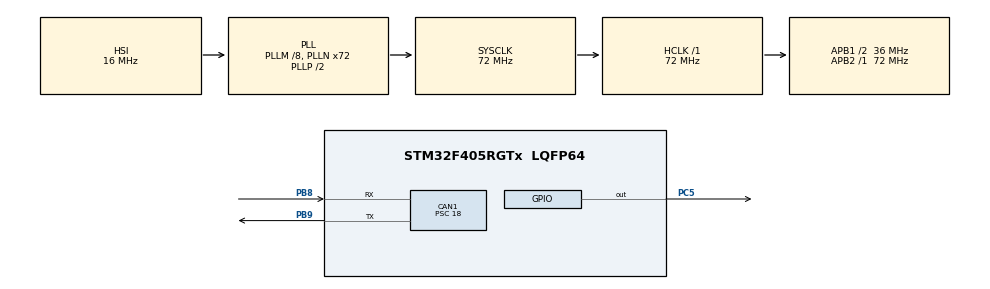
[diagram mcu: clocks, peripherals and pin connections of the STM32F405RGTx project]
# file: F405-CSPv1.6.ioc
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CAN1.BS1=CAN_BS1_2TQ
CAN1.CalculateBaudRate=500000
CAN1.CalculateTimeBit=2000
CAN1.CalculateTimeQuantum=500.0
CAN1.Prescaler=18
FREERTOS.Tasks01=defaultTask,24,128,StartDefaultTask,Default,NULL,Dynamic,NULL,NULL;canReceive,32,128,CANReceive,Default,NULL,Dynamic,NULL,NULL;canSend,8,128,CANSend,Default,NULL,Dynamic,NULL,NULL
FREERTOS.configUSE_NEWLIB_REENTRANT=1
Mcu.Family=STM32F4
Mcu.Name=STM32F405RGTx
Mcu.Package=LQFP64
NVIC.CAN1_RX0_IRQn=true\:5\:0\:false\:false\:true\:true\:true\:true\:true
NVIC.PriorityGroup=NVIC_PRIORITYGROUP_4
NVIC.TIM1_UP_TIM10_IRQn=true\:15\:0\:false\:false\:true\:false\:false\:true\:true
NVIC.TimeBase=TIM1_UP_TIM10_IRQn
NVIC.TimeBaseIP=TIM1
PA13.Mode=Serial_Wire
PA13.Signal=SYS_JTMS-SWDIO
PA14.Mode=Serial_Wire
PA14.Signal=SYS_JTCK-SWCLK
PB6.Signal=I2C1_SCL
PB7.Signal=I2C1_SDA
PB8.Mode=CAN_Activate
PB8.Signal=CAN1_RX
PB9.Mode=CAN_Activate
PB9.Signal=CAN1_TX
PC5.Signal=GPIO_Output
PH0-OSC_IN.Mode=HSE-External-Oscillator
PH0-OSC_IN.Signal=RCC_OSC_IN
PH1-OSC_OUT.Mode=HSE-External-Oscillator
PH1-OSC_OUT.Signal=RCC_OSC_OUT
ProjectManager.HeapSize=0x200
ProjectManager.StackSize=0x400
ProjectManager.TargetToolchain=STM32CubeIDE
RCC.48MHZClocksFreq_Value=36000000
RCC.AHBFreq_Value=72000000
RCC.APB1CLKDivider=RCC_HCLK_DIV2
RCC.APB1Freq_Value=36000000
RCC.APB1TimFreq_Value=72000000
RCC.APB2Freq_Value=72000000
RCC.APB2TimFreq_Value=72000000
RCC.CortexFreq_Value=72000000
RCC.HCLKFreq_Value=72000000
RCC.HSE_VALUE=25000000
RCC.HSI_VALUE=16000000
RCC.LSE_VALUE=32768
RCC.PLLM=8
RCC.PLLN=72
RCC.SYSCLKFreq_VALUE=72000000
RCC.SYSCLKSource=RCC_SYSCLKSOURCE_PLLCLK
RCC.VCOOutputFreq_Value=144000000
VP_FREERTOS_VS_CMSIS_V2.Mode=CMSIS_V2
VP_SYS_VS_tim1.Mode=TIM1
board=custom

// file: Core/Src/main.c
/* USER CODE BEGIN Header */
/**
  ******************************************************************************
  * @file           : main.c
  * @brief          : Main program body
  ******************************************************************************
  * @attention
  *
  * Copyright (c) 2025 STMicroelectronics.
  * All rights reserved.
  *
  * This software is licensed under terms that can be found in the LICENSE file
  * in the root directory of this software component.
  * If no LICENSE file comes with this software, it is provided AS-IS.
  *
  ******************************************************************************
  */
/* USER CODE END Header */
#include "main.h"
#include "cmsis_os.h"

/* USER CODE BEGIN Includes */
#include <stdio.h>
#include <string.h>
#include "stream_buffer.h"

#include <csp/csp.h>
#include <csp/interfaces/csp_if_can.h>
#include <csp/interfaces/csp_if_i2c.h>
#include <csp/csp_rtable.h>
/* USER CODE END Includes */

/* USER CODE BEGIN PTD */
extern csp_conf_t csp_conf;
csp_can_interface_data_t can_ifdata;
csp_i2c_interface_data_t i2c_ifdata;
csp_iface_t i2c_iface;
csp_iface_t can_iface;
/* USER CODE END PTD */

/* USER CODE BEGIN PD */
#define UART_RX_STREAM_SIZE 256
/* USER CODE END PD */

CAN_HandleTypeDef hcan1;

/* Definitions for defaultTask */
osThreadId_t defaultTaskHandle;
const osThreadAttr_t defaultTask_attributes = {
  .name = "defaultTask",
  .stack_size = 128 * 4,
  .priority = (osPriority_t) osPriorityNormal,
};
/* Definitions for canReceive */
osThreadId_t canReceiveHandle;
const osThreadAttr_t canReceive_attributes = {
  .name = "canReceive",
  .stack_size = 128 * 4,
  .priority = (osPriority_t) osPriorityAboveNormal,
};
/* Definitions for canSend */
osThreadId_t canSendHandle;
const osThreadAttr_t canSend_attributes = {
  .name = "canSend",
  .stack_size = 128 * 4,
  .priority = (osPriority_t) osPriorityLow,
};
/* USER CODE BEGIN PV */
uint32_t server_received = 0;

//static uint8_t  rx_byte;
//static StreamBufferHandle_t xUartRxStream;
/* USER CODE END PV */

void SystemClock_Config(void);
static void MX_GPIO_Init(void);
static void MX_CAN1_Init(void);
void StartDefaultTask(void *argument);
void CANReceive(void *argument);
void CANSend(void *argument);

/* USER CODE BEGIN 0 */
/*TX FUNCTION*/
static int csp_can_tx_frame(void *driver_data, uint32_t id, const uint8_t *data, uint8_t dlc){

	HAL_GPIO_TogglePin(GPIOC, GPIO_PIN_5);

	CAN_TxHeaderTypeDef txHeader;
	txHeader.DLC = dlc;
	txHeader.IDE = CAN_ID_EXT;
	txHeader.RTR = CAN_RTR_DATA;
	txHeader.ExtId = id;
	txHeader.TransmitGlobalTime = DISABLE;

	uint32_t canMailBox;
	if (HAL_CAN_AddTxMessage(&hcan1, &txHeader, (uint8_t *)data, &canMailBox) != HAL_OK) {
	        return CSP_ERR_DRIVER;
	    }
	return CSP_ERR_NONE;
}

//static int csp_i2c_tx_frame(){
//	return CSP_ERR_NONE;
//}

/*CALLBACK*/
void HAL_CAN_RxFifo0MsgPendingCallback(CAN_HandleTypeDef *hcan) {
	CAN_RxHeaderTypeDef rxHeader;
	uint8_t rxData[8];

	CSP_BASE_TYPE xCspTaskWoken = pdFALSE;
	 if (HAL_CAN_GetRxMessage(hcan, CAN_RX_FIFO0, &rxHeader, rxData) == HAL_OK) {
		 csp_can_rx(&can_iface, rxHeader.ExtId, rxData, rxHeader.DLC, &xCspTaskWoken);
		 HAL_GPIO_TogglePin(GPIOC, GPIO_PIN_5);

	    	if(xCspTaskWoken) {
	    		portYIELD_FROM_ISR(xCspTaskWoken);
	    	}
	 }
}

//void HAL_UART_RxCpltCallback(UART_HandleTypeDef *huart) {
////	HAL_GPIO_TogglePin(GPIOC, GPIO_PIN_5);
//    if (huart == &huart6) {
//        BaseType_t xHigher = pdFALSE;
//        xStreamBufferSendFromISR(xUartRxStream, &rx_byte, 1, &xHigher);
//
//        HAL_UART_Transmit(&huart6, &rx_byte, 1, 100);
//        HAL_UART_Receive_IT(&huart6, &rx_byte, 1);
//
//        portYIELD_FROM_ISR(xHigher);
//    }
//}

/*INTERFACE INIT*/
static void can_csp_init(void) {

	can_ifdata.tx_func        = csp_can_tx_frame;
	can_iface.name            = "can";
	can_iface.driver_data     = &hcan1;
	can_iface.interface_data  = &can_ifdata;

	csp_can_add_interface(&can_iface);
 }

//static void i2c_csp_init(void) {
//
//	i2c_ifdata.tx_func        = csp_i2c_tx_frame;
//	i2c_iface.name            = "i2c";
//	i2c_iface.driver_data     = &hi2c1;
//	i2c_iface.interface_data  = &i2c_ifdata;
//
//	csp_i2c_add_interface(&i2c_iface);
//}

/* USER CODE END 0 */

int main(void)
{

  /* MCU Configuration--------------------------------------------------------*/

  /* Reset of all peripherals, Initializes the Flash interface and the Systick. */
  HAL_Init();

  /* Configure the system clock */
  SystemClock_Config();

  /* Initialize all configured peripherals */
  MX_GPIO_Init();
  MX_CAN1_Init();
  /* USER CODE BEGIN 2 */
  /*CAN INIT*/
  HAL_CAN_Start(&hcan1);
  HAL_CAN_ActivateNotification(&hcan1, CAN_IT_RX_FIFO0_MSG_PENDING);

  /*UART INIT*/
//  xUartRxStream = xStreamBufferCreate(UART_RX_STREAM_SIZE, 1);
//  HAL_UART_Receive_IT(&huart6, &rx_byte, 1);

  /*CSP INIT*/
  csp_conf_get_defaults(&csp_conf);
  csp_conf.address = 2;
  csp_init(&csp_conf);

  /*CSP INTERFACE INIT*/
  can_csp_init();
//  i2c_csp_init();

  /*CSP ROUTER INIT*/
  csp_route_start_task(500, 6);
  csp_rtable_set(1, CSP_ID_HOST_SIZE, &can_iface, CSP_NO_VIA_ADDRESS);

  /* USER CODE END 2 */

  /* Init scheduler */
  osKernelInitialize();

  /* Create the thread(s) */
  /* creation of defaultTask */
  defaultTaskHandle = osThreadNew(StartDefaultTask, NULL, &defaultTask_attributes);

  /* creation of canReceive */
  canReceiveHandle = osThreadNew(CANReceive, NULL, &canReceive_attributes);

  /* creation of canSend */
//  canSendHandle = osThreadNew(CANSend, NULL, &canSend_attributes);

  /* Start scheduler */
  osKernelStart();

  /* We should never get here as control is now taken by the scheduler */
  /* Infinite loop */
  while (1)
  {

  }
}

void SystemClock_Config(void)
{
  RCC_OscInitTypeDef RCC_OscInitStruct = {0};
  RCC_ClkInitTypeDef RCC_ClkInitStruct = {0};

  /** Configure the main internal regulator output voltage
  */
  __HAL_RCC_PWR_CLK_ENABLE();
  __HAL_PWR_VOLTAGESCALING_CONFIG(PWR_REGULATOR_VOLTAGE_SCALE1);

  /** Initializes the RCC Oscillators according to the specified parameters
  * in the RCC_OscInitTypeDef structure.
  */
  RCC_OscInitStruct.OscillatorType = RCC_OSCILLATORTYPE_HSI;
  RCC_OscInitStruct.HSIState = RCC_HSI_ON;
  RCC_OscInitStruct.HSICalibrationValue = RCC_HSICALIBRATION_DEFAULT;
  RCC_OscInitStruct.PLL.PLLState = RCC_PLL_ON;
  RCC_OscInitStruct.PLL.PLLSource = RCC_PLLSOURCE_HSI;
  RCC_OscInitStruct.PLL.PLLM = 8;
  RCC_OscInitStruct.PLL.PLLN = 72;
  RCC_OscInitStruct.PLL.PLLP = RCC_PLLP_DIV2;
  RCC_OscInitStruct.PLL.PLLQ = 4;
  if (HAL_RCC_OscConfig(&RCC_OscInitStruct) != HAL_OK)
  {
    Error_Handler();
  }

  /** Initializes the CPU, AHB and APB buses clocks
  */
  RCC_ClkInitStruct.ClockType = RCC_CLOCKTYPE_HCLK|RCC_CLOCKTYPE_SYSCLK
                              |RCC_CLOCKTYPE_PCLK1|RCC_CLOCKTYPE_PCLK2;
  RCC_ClkInitStruct.SYSCLKSource = RCC_SYSCLKSOURCE_PLLCLK;
  RCC_ClkInitStruct.AHBCLKDivider = RCC_SYSCLK_DIV1;
  RCC_ClkInitStruct.APB1CLKDivider = RCC_HCLK_DIV2;
  RCC_ClkInitStruct.APB2CLKDivider = RCC_HCLK_DIV1;

  if (HAL_RCC_ClockConfig(&RCC_ClkInitStruct, FLASH_LATENCY_2) != HAL_OK)
  {
    Error_Handler();
  }
}

static void MX_CAN1_Init(void)
{

  hcan1.Instance = CAN1;
  hcan1.Init.Prescaler = 18;
  hcan1.Init.Mode = CAN_MODE_NORMAL;
  hcan1.Init.SyncJumpWidth = CAN_SJW_1TQ;
  hcan1.Init.TimeSeg1 = CAN_BS1_2TQ;
  hcan1.Init.TimeSeg2 = CAN_BS2_1TQ;
  hcan1.Init.TimeTriggeredMode = DISABLE;
  hcan1.Init.AutoBusOff = DISABLE;
  hcan1.Init.AutoWakeUp = DISABLE;
  hcan1.Init.AutoRetransmission = DISABLE;
  hcan1.Init.ReceiveFifoLocked = DISABLE;
  hcan1.Init.TransmitFifoPriority = DISABLE;
  if (HAL_CAN_Init(&hcan1) != HAL_OK)
  {
    Error_Handler();
  }
  /* USER CODE BEGIN CAN1_Init 2 */
  CAN_FilterTypeDef filterconf = {0};
  filterconf.FilterBank = 0;
  filterconf.FilterMode = CAN_FILTERMODE_IDMASK;
  filterconf.FilterScale = CAN_FILTERSCALE_32BIT;
  filterconf.FilterIdHigh = 0;
  filterconf.FilterIdLow = 0;
  filterconf.FilterMaskIdHigh = 0;
  filterconf.FilterMaskIdLow = 0;
  filterconf.FilterFIFOAssignment = CAN_RX_FIFO0;
  filterconf.FilterActivation = ENABLE;
  filterconf.SlaveStartFilterBank = 14;
  HAL_CAN_ConfigFilter(&hcan1, &filterconf);
  /* USER CODE END CAN1_Init 2 */

}

static void MX_GPIO_Init(void)
{
  GPIO_InitTypeDef GPIO_InitStruct = {0};

  /* GPIO Ports Clock Enable */
  __HAL_RCC_GPIOH_CLK_ENABLE();
  __HAL_RCC_GPIOC_CLK_ENABLE();
  __HAL_RCC_GPIOA_CLK_ENABLE();
  __HAL_RCC_GPIOB_CLK_ENABLE();

  /*Configure GPIO pin Output Level */
  HAL_GPIO_WritePin(GPIOC, GPIO_PIN_5, GPIO_PIN_RESET);

  /*Configure GPIO pin : PC5 */
  GPIO_InitStruct.Pin = GPIO_PIN_5;
  GPIO_InitStruct.Mode = GPIO_MODE_OUTPUT_PP;
  GPIO_InitStruct.Pull = GPIO_NOPULL;
  GPIO_InitStruct.Speed = GPIO_SPEED_FREQ_LOW;
  HAL_GPIO_Init(GPIOC, &GPIO_InitStruct);

  /*Configure GPIO pins : PB6 PB7 */
  GPIO_InitStruct.Pin = GPIO_PIN_6|GPIO_PIN_7;
  GPIO_InitStruct.Mode = GPIO_MODE_AF_OD;
  GPIO_InitStruct.Pull = GPIO_NOPULL;
  GPIO_InitStruct.Speed = GPIO_SPEED_FREQ_VERY_HIGH;
  GPIO_InitStruct.Alternate = GPIO_AF4_I2C1;
  HAL_GPIO_Init(GPIOB, &GPIO_InitStruct);

}

void StartDefaultTask(void *argument)
{
  /* USER CODE BEGIN 5 */
  /* Infinite loop */
  for(;;)
  {
	  osDelay(100);
  }
  /* USER CODE END 5 */
}

void CANReceive(void *argument)
{
  /* USER CODE BEGIN CANReceive */
	/* Create socket with no specific socket options, e.g. accepts CRC32, HMAC, XTEA, etc. if enabled during compilation */
	csp_socket_t *sock = csp_socket(CSP_SO_NONE);

	/* Bind socket to all ports, e.g. all incoming connections will be handled here */
	csp_bind(sock, CSP_ANY);

	/* Create a backlog of 10 connections, i.e. up to 10 new connections can be queued */
	csp_listen(sock, 10);
  /* Infinite loop */
  for(;;)
  {
	  /* Wait for a new connection, 10000 mS timeout */
	  	csp_conn_t *conn;
	  	if ((conn = csp_accept(sock, 10000)) == NULL) {
	  		/* timeout */
	  		continue;
	  	}

	  	/* Read packets on connection, timout is 100 mS */
	  	csp_packet_t *packet;
	  	while ((packet = csp_read(conn, 100)) != NULL) {
	  		switch (csp_conn_dport(conn)) {
	  		case 0:
	  		case 1:
	  		case 26:
	  		case 3:
	  		case 48:
	  		case 8:
	  		case 10:
	  			/* Process packet here */
	  			csp_log_info("Packet received on MY_SERVER_PORT: %s", (char *) packet->data);
	  			csp_buffer_free(packet);
	  			++server_received;
	  			break;

	  		default:
	  			/* Call the default CSP service handler, handle pings, buffer use, etc. */
	  	//				csp_service_handler(conn, packet);
	  			break;
	  		}
	  	}
  }
  /* USER CODE END CANReceive */
}

void CANSend(void *argument)
{
  /* USER CODE BEGIN CANSend */
	const uint8_t DST  = 2;   // Receiver Addr
	const uint8_t PORT = 10;
	const char *msg = "Hello from F405";
  /* Infinite loop */
  for(;;)
  {
	csp_conn_t *conn = csp_connect(CSP_PRIO_NORM, DST, PORT, 1000 /*ms*/, CSP_O_NONE);
	if (conn == NULL) {
	  osDelay(1000);
	  continue;
	}

	/* Cấp packet và copy payload */
	size_t len = strlen(msg);
	csp_packet_t *pkt = csp_buffer_get(len);
	if (pkt == NULL) {
	  csp_close(conn);
	  osDelay(1000);
	  continue;
	}

	memcpy(pkt->data, msg, len);
	pkt->length = len;

	/* Gửi packet, nếu lỗi thì phải free buffer */
	if (csp_send(conn, pkt, 1000 /*ms*/) != CSP_ERR_NONE) {
	  csp_buffer_free(pkt);
	}

	csp_close(conn);

	osDelay(1000);
  }
  /* USER CODE END CANSend */
}

void HAL_TIM_PeriodElapsedCallback(TIM_HandleTypeDef *htim)
{
  if (htim->Instance == TIM1) {
    HAL_IncTick();
  }
}

void Error_Handler(void)
{
  __disable_irq();
  while (1)
  {
  }
}
